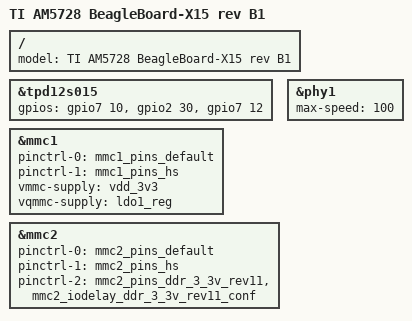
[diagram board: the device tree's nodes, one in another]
#include "am57xx-beagle-x15-common.dtsi"
/ {
	model = "TI AM5728 BeagleBoard-X15 rev B1";
};
&tpd12s015 {
	gpios = <&gpio7 10 GPIO_ACTIVE_HIGH>,	 
		<&gpio2 30 GPIO_ACTIVE_HIGH>,	 
		<&gpio7 12 GPIO_ACTIVE_HIGH>;	 
};
&mmc1 {
	pinctrl-names = "default", "hs";
	pinctrl-0 = <&mmc1_pins_default>;
	pinctrl-1 = <&mmc1_pins_hs>;
	vmmc-supply = <&vdd_3v3>;
	vqmmc-supply = <&ldo1_reg>;
};
&mmc2 {
	pinctrl-names = "default", "hs", "ddr_3_3v";
	pinctrl-0 = <&mmc2_pins_default>;
	pinctrl-1 = <&mmc2_pins_hs>;
	pinctrl-2 = <&mmc2_pins_ddr_3_3v_rev11 &mmc2_iodelay_ddr_3_3v_rev11_conf>;
};
&phy1 {
	max-speed = <100>;
};
